# RA register map
Vendor: Renesas; Series: All Chips; File version: x.xx
Registers are 32-bit, read-write, reset 0x0 unless marked. A register's access mark holds for its fields unless they carry their own. Offsets are from the block's base; [hi:lo] are bit positions; {n}, {i} and the like mark numbered series; 'fields as' and 'values as' point back to an identical list.

## R_FACI_LP — Flash Application Command Interface
Base 0x407EC000
0x90 DFLCTL 8-bit — Flash P/E Mode Control Register
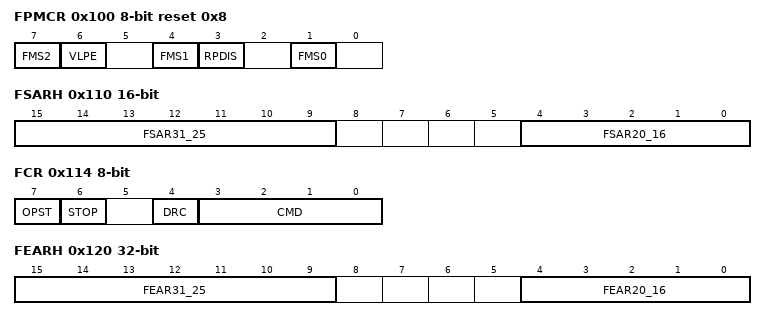
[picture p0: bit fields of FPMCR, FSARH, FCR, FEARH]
0x100 FPMCR 8-bit reset 0x8 — Flash P/E Mode Control Register
  [7] FMS2 — Flash Operating Mode Select 2. Refer to the description of the FMS0 bit.
  [6] VLPE — Low-Voltage P/E Mode Enable
    0=Low-voltage programming is disabled; 1=Low-voltage programming is enabled
  [4] FMS1 — The bit to make data flash a programming mode Refer to the description of the FMS0 bit.
  [3] RPDIS — Code Flash P/E Disable
    0=The programming of the code flash is enabled; 1=The programming of the code flash is disabled
  [1] FMS0 — Flash Operating Mode Select 0 FMS2,1,0: 000: Read mode 011: Discharge mode 1 111: Discharge mode 2 101: Code Flash P/E mode 010: Data flash P/E mode Others: Setting prohibited.
0x104 FASR 8-bit — Flash Area Select Register
  [0] EXS — Extra area select
    0=User area or data area; 1=Extra area
0x108 FSARL 16-bit — Flash Processing Start Address Register L
  [15:0] FSAR15_0 — Start address
0x110 FSARH 16-bit — Flash Processing Start Address Register H
  [15:9] FSAR31_25 — Start address
  [4:0] FSAR20_16 — Start address
0x114 FCR 8-bit — Flash Control Register
  [7] OPST — Processing Start
    0=Processing stops; 1=Processing starts
  [6] STOP — Forced Processing Stop
  [4] DRC — Data Read Completion
    0=Data is not read or next data is requested; 1=Data reading is completed
  [3:0] CMD — Software Command Setting
    1=Program; 3=Blank check; 4=Block erase; 5=Consecutive read; 7=Chip erase; other=others (Setting prohibited)
0x118 FEARL 16-bit — Flash Processing End Address Register L
  [15:0] FEAR15_0 — End address
0x120 FEARH — Flash Processing End Address Register H
  [15:9] FEAR31_25 — End address
  [4:0] FEAR20_16 — End address
0x124 FRESETR — Flash Reset Register
  [0] FRESET — Software Reset of the registers
    0=No effect; 1=The registers relates to the flash programming are reset
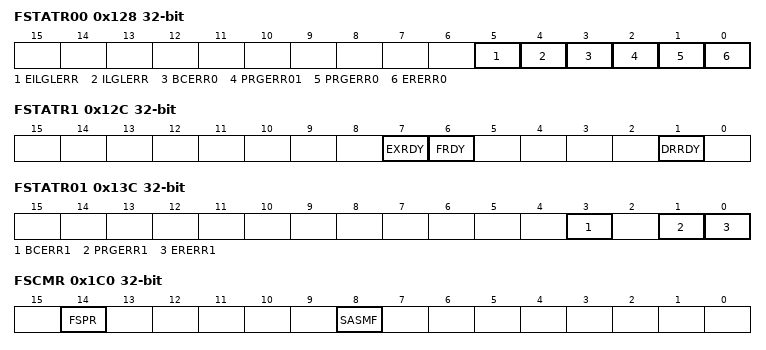
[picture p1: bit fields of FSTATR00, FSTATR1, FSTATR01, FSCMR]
0x128 FSTATR00 ro (reset mask 0xFFFFFFEF) — Flash Status Register00
  [5] EILGLERR — Extra Area Illegal Command Error Flag
    0=No illegal command or illegal access to the extra area is detected; 1=An illegal command or illegal access to the extra area is detected
  [4] ILGLERR — Illegal Command Error Flag
    0=No illegal software command or illegal access is detected; 1=An illegal command or illegal access is detected
  [3] BCERR0 — Blank Check Error Flag0
    0=Blank checking terminates normally; 1=An error occurs during blank checking
  [2] PRGERR01 — Program Error Flag 01
    0=Programming by the FEXCR register terminates normally; 1=An error occurs during programming
  [1] PRGERR0 — Program Error Flag0
    0=Programming terminates normally; 1=An error occurs during programming
  [0] ERERR0 — Erase Error Flag0
    0=Erasure terminates normally; 1=An error occurs during erasure
0x12C FSTATR1 ro — Flash Status Register1
  [7] EXRDY — End status signal of a Extra programming sequencer
    0=Other than below; 1=The software command of the FEXCR register is terminated
  [6] FRDY — End status signal of a sequencer
    0=Other than below; 1=The software command of the FCR register is terminated
  [1] DRRDY — Data read request
    0=Other than below; 1=The read processing of the consecutive read command at each address is terminated and read data is stored to the FRBH and FRBL registers
0x130 FWBL0 — Flash Write Buffer Register L0
  [15:0] WDATA — Program data of the program command
0x138 FWBH0 — Flash Write Buffer Register H0
  [15:0] WDATA — Program data of the program command
0x13C FSTATR01 ro — Flash Status Register01
  [3] BCERR1 — Blank Check Error Flag1
    values as FSTATR00.BCERR0
  [1] PRGERR1 — Program Error Flag1
    values as FSTATR00.PRGERR0
  [0] ERERR1 — Erase Error Flag1
    values as FSTATR00.ERERR0
0x140 FWBL1 — Flash Write Buffer Register L1
  [15:0] WDATA47_32 — Program data of the program command
0x144 FWBH1 — Flash Write Buffer Register H1
  [15:0] WDATA63_48 — Program data of the program command
0x148 FRBL1 ro — Flash Read Buffer Register L1
  [15:0] RDATA47_32 — Read data of the consecutive read command
0x14C FRBH1 ro — Flash Read Buffer Register H1
  [15:0] RDATA63_48 — Read data of the consecutive read command
0x180 FPR wo (reset mask 0xFFFFFF00) — Protection Unlock Register
  [7:0] FPR
0x184 FPSR ro — Protection Unlock Status Register
  [0] PERR — Protect Error Flag
    0=No error; 1=An error occurs
0x188 FRBL0 ro — Flash Read Buffer Register L0
  [15:0] RDATA — Read data of the consecutive read command
0x190 FRBH0 ro — Flash Read Buffer Register H0
  [15:0] RDATA — Read data of the consecutive read command
0x1C0 FSCMR ro (reset mask 0xFFFFBEFF) — Flash Start-Up Setting Monitor Register
  [14] FSPR — Access Window Protection Flag
  [8] SASMF — Start-up Area Setting Monitor Flag
0x1C8 FAWSMR ro (reset mask 0xFFFFF000) — Flash Access Window Start Address Monitor Register
  [11:0] FAWS — Flash Access Window Start Address
0x1D0 FAWEMR ro (reset mask 0xFFFFF000) — Flash Access Window End Address Monitor Register
  [11:0] FAWE — Flash Access Window End Address
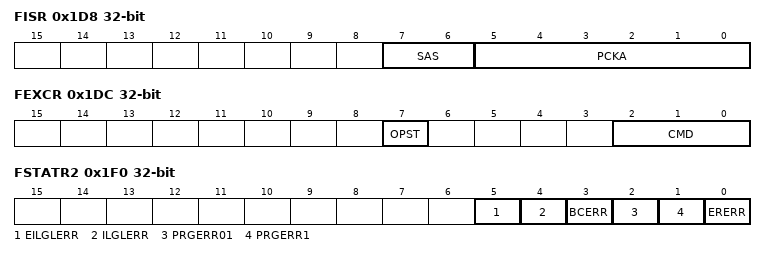
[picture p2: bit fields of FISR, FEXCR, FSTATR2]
0x1D8 FISR — Flash Initial Setting Register
  [7:6] SAS — Temporary boot swap mode
    2=The start-up area is switched to the default area temporarily; 3=The start-up area is switched to the alternate area temporarily; other=others (The start-up area is selected according to the start-up area settings of the extra area.)
  [5:0] PCKA — Peripheral Clock Notification
0x1DC FEXCR — Flash Extra Area Control Register
  [7] OPST — Software Command Setting
    0=Processing stops; 1=Processing starts
  [2:0] CMD — Processing Start)
    1=Start-up area selection and security setting; 2=Access window information program; {v}=OCDID{v-2} program (v=3..6); 7=Extra area clear; other=others (Setting prohibited)
0x1E0 FEAML ro — Flash Error Address Monitor Register L
  [15:0] FEAM — Flash Error Address Monitor Register
0x1E8 FEAMH ro — Flash Error Address Monitor Register H
  [15:0] FEAM — Flash Error Address Monitor Register
0x1F0 FSTATR2 ro — Flash Status Register2
  [5] EILGLERR — Extra Area Illegal Command Error Flag
  [4] ILGLERR — Illegal Command Error Flag
  [3] BCERR — Blank Check Error Flag
  [2] PRGERR01 rw — Program Error Flag 01
  [1] PRGERR1 — Program Error Flag
  [0] ERERR — Erase Error Flag
0x3FB0 FENTRYR_MF4 16-bit — Flash P/E Mode Entry Register for MF4
0x3FB2 FENTRYR 16-bit — Flash P/E Mode Entry Register
0x3FC0 FLWAITR 8-bit — Flash Wait Cycle Register
0x3FC8 PFBER 8-bit — Prefetch Buffer Enable Register
